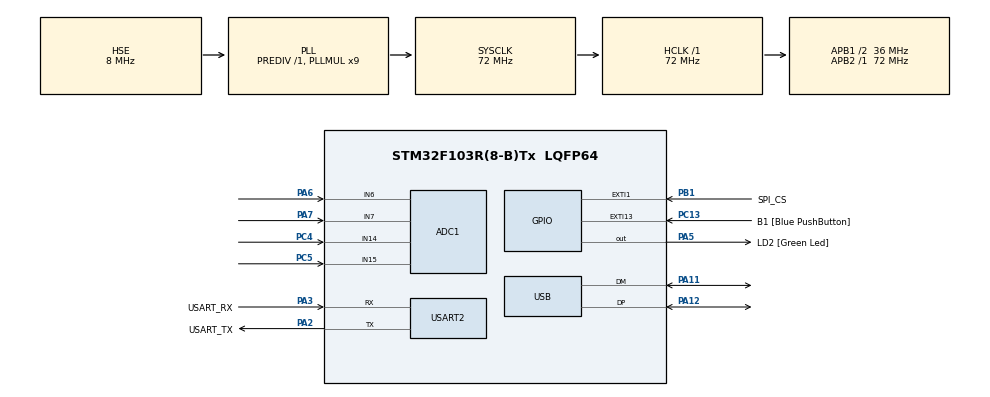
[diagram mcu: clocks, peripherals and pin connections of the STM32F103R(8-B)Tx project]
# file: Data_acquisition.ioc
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ADC1.Channel-6\#ChannelRegularConversion=ADC_CHANNEL_15
ADC1.Channel-7\#ChannelRegularConversion=ADC_CHANNEL_6
ADC1.Channel-9\#ChannelRegularConversion=ADC_CHANNEL_7
ADC1.ContinuousConvMode=ENABLE
ADC1.EnableRegularConversion=ENABLE
ADC1.ExternalTrigConv=ADC_SOFTWARE_START
ADC1.NbrOfConversion=3
ADC1.NbrOfConversionFlag=1
ADC1.Rank-6\#ChannelRegularConversion=1
ADC1.Rank-7\#ChannelRegularConversion=2
ADC1.Rank-9\#ChannelRegularConversion=3
ADC1.SamplingTime-6\#ChannelRegularConversion=ADC_SAMPLETIME_55CYCLES_5
ADC1.SamplingTime-7\#ChannelRegularConversion=ADC_SAMPLETIME_1CYCLE_5
ADC1.SamplingTime-9\#ChannelRegularConversion=ADC_SAMPLETIME_1CYCLE_5
ADC1.master=1
Dma.ADC1.0.Direction=DMA_PERIPH_TO_MEMORY
Dma.ADC1.0.Instance=DMA1_Channel1
Dma.ADC1.0.MemDataAlignment=DMA_MDATAALIGN_HALFWORD
Dma.ADC1.0.MemInc=DMA_MINC_ENABLE
Dma.ADC1.0.Mode=DMA_CIRCULAR
Dma.ADC1.0.PeriphDataAlignment=DMA_PDATAALIGN_HALFWORD
Dma.ADC1.0.PeriphInc=DMA_PINC_DISABLE
Dma.ADC1.0.Priority=DMA_PRIORITY_LOW
Dma.Request0=ADC1
Mcu.Family=STM32F1
Mcu.Name=STM32F103R(8-B)Tx
Mcu.Package=LQFP64
NVIC.DMA1_Channel1_IRQn=true\:0\:0\:false\:false\:true\:false\:true\:true
NVIC.EXTI15_10_IRQn=true\:0\:0\:false\:false\:true\:true\:true\:true
NVIC.EXTI1_IRQn=true\:0\:0\:false\:false\:true\:true\:true\:true
NVIC.PriorityGroup=NVIC_PRIORITYGROUP_4
NVIC.USB_LP_CAN1_RX0_IRQn=true\:0\:0\:false\:false\:true\:false\:true\:true
PA11.Mode=Device
PA11.Signal=USB_DM
PA12.Mode=Device
PA12.Signal=USB_DP
PA13.GPIO_Label=TMS
PA13.Mode=Serial_Wire
PA13.Signal=SYS_JTMS-SWDIO
PA14.GPIO_Label=TCK
PA14.Mode=Serial_Wire
PA14.Signal=SYS_JTCK-SWCLK
PA2.GPIO_Label=USART_TX
PA2.GPIO_Mode=GPIO_MODE_AF_PP
PA2.GPIO_PuPd=GPIO_NOPULL
PA2.GPIO_Speed=GPIO_SPEED_FREQ_LOW
PA2.Mode=Asynchronous
PA2.Signal=USART2_TX
PA3.GPIO_Label=USART_RX
PA3.GPIO_Mode=GPIO_MODE_AF_PP
PA3.GPIO_PuPd=GPIO_NOPULL
PA3.GPIO_Speed=GPIO_SPEED_FREQ_LOW
PA3.Mode=Asynchronous
PA3.Signal=USART2_RX
PA5.GPIO_Label=LD2 [Green Led]
PA5.GPIO_ModeDefaultOutputPP=GPIO_MODE_OUTPUT_PP
PA5.GPIO_PuPd=GPIO_NOPULL
PA5.GPIO_Speed=GPIO_SPEED_FREQ_LOW
PA5.Signal=GPIO_Output
PA6.Signal=ADCx_IN6
PA7.Signal=ADCx_IN7
PB1.GPIO_Label=SPI_CS
PB1.GPIO_ModeDefaultEXTI=GPIO_MODE_IT_FALLING
PB1.GPIO_PuPd=GPIO_NOPULL
PB1.Signal=GPXTI1
PB3.GPIO_Label=SWO
PB3.Signal=SYS_JTDO-TRACESWO
PC13-TAMPER-RTC.GPIO_Label=B1 [Blue PushButton]
PC13-TAMPER-RTC.GPIO_ModeDefaultEXTI=GPIO_MODE_IT_FALLING
PC13-TAMPER-RTC.GPIO_PuPd=GPIO_NOPULL
PC13-TAMPER-RTC.Signal=GPXTI13
PC14-OSC32_IN.Mode=LSE-External-Oscillator
PC14-OSC32_IN.Signal=RCC_OSC32_IN
PC15-OSC32_OUT.Mode=LSE-External-Oscillator
PC15-OSC32_OUT.Signal=RCC_OSC32_OUT
PC4.Signal=ADCx_IN14
PC5.Signal=ADCx_IN15
PD0-OSC_IN.Mode=HSE-External-Clock-Source
PD0-OSC_IN.Signal=RCC_OSC_IN
PD1-OSC_OUT.Mode=HSE-External-Clock-Source
PD1-OSC_OUT.Signal=RCC_OSC_OUT
ProjectManager.HeapSize=0x200
ProjectManager.StackSize=0x400
ProjectManager.TargetToolchain=STM32CubeIDE
RCC.ADCPresc=RCC_ADCPCLK2_DIV6
RCC.AHBFreq_Value=72000000
RCC.APB1CLKDivider=RCC_HCLK_DIV2
RCC.APB1Freq_Value=36000000
RCC.APB1TimFreq_Value=72000000
RCC.APB2Freq_Value=72000000
RCC.APB2TimFreq_Value=72000000
RCC.HCLKFreq_Value=72000000
RCC.PLLMUL=RCC_PLL_MUL9
RCC.PLLSourceVirtual=RCC_PLLSOURCE_HSE
RCC.RTCClockSelection=RCC_RTCCLKSOURCE_LSE
RCC.SYSCLKFreq_VALUE=72000000
RCC.SYSCLKSource=RCC_SYSCLKSOURCE_PLLCLK
RCC.USBFreq_Value=48000000
RCC.USBPrescaler=RCC_USBCLKSOURCE_PLL_DIV1_5
SH.ADCx_IN14.0=ADC1_IN14,IN14
SH.ADCx_IN15.0=ADC1_IN15,IN15
SH.ADCx_IN6.0=ADC1_IN6,IN6
SH.ADCx_IN7.0=ADC1_IN7,IN7
USART2.VirtualMode=VM_ASYNC
USB_DEVICE.CLASS_NAME_FS=CDC
USB_DEVICE.PRODUCT_STRING_CDC_FS=STM32 Virtual ComPort USB
USB_DEVICE.VirtualMode=Cdc
USB_DEVICE.VirtualModeFS=Cdc_FS
VP_USB_DEVICE_VS_USB_DEVICE_CDC_FS.Mode=CDC_FS
board=NUCLEO-F103RB

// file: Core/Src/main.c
/* USER CODE BEGIN Header */
/**
  ******************************************************************************
  * @file           : main.c
  * @brief          : Main program body
  ******************************************************************************
  * @attention
  *
  * Copyright (c) 2022 STMicroelectronics.
  * All rights reserved.
  *
  * This software is licensed under terms that can be found in the LICENSE file
  * in the root directory of this software component.
  * If no LICENSE file comes with this software, it is provided AS-IS.
  *
  ******************************************************************************
  */
/* USER CODE END Header */
#include "main.h"
#include "usb_device.h"

/* USER CODE BEGIN PD */
// Buffer length set at 6600 (2200 per one channel)
#define DMA_ADC_BUF (6600)
/* USER CODE END PD */

ADC_HandleTypeDef hadc1;
DMA_HandleTypeDef hdma_adc1;

UART_HandleTypeDef huart2;

/* USER CODE BEGIN PV */
volatile uint16_t adcResultsDMA[DMA_ADC_BUF];
/* USER CODE END PV */

void SystemClock_Config(void);
static void MX_GPIO_Init(void);
static void MX_DMA_Init(void);
static void MX_ADC1_Init(void);
static void MX_USART2_UART_Init(void);

int main(void)
{

  /* MCU Configuration--------------------------------------------------------*/

  /* Reset of all peripherals, Initializes the Flash interface and the Systick. */
  HAL_Init();

  /* Configure the system clock */
  SystemClock_Config();

  /* Initialize all configured peripherals */
  MX_GPIO_Init();
  MX_DMA_Init();
  MX_ADC1_Init();
  MX_USB_DEVICE_Init();
  MX_USART2_UART_Init();
  /* USER CODE BEGIN 2 */
  // Start of DMA ADC measurements
  HAL_ADC_Start_DMA(&hadc1, (uint32_t*)adcResultsDMA, DMA_ADC_BUF);
  /* USER CODE END 2 */

  /* Infinite loop */
  while (1)
  {

  }
}

void SystemClock_Config(void)
{
  RCC_OscInitTypeDef RCC_OscInitStruct = {0};
  RCC_ClkInitTypeDef RCC_ClkInitStruct = {0};
  RCC_PeriphCLKInitTypeDef PeriphClkInit = {0};

  /** Initializes the RCC Oscillators according to the specified parameters
  * in the RCC_OscInitTypeDef structure.
  */
  RCC_OscInitStruct.OscillatorType = RCC_OSCILLATORTYPE_HSE;
  RCC_OscInitStruct.HSEState = RCC_HSE_BYPASS;
  RCC_OscInitStruct.HSEPredivValue = RCC_HSE_PREDIV_DIV1;
  RCC_OscInitStruct.HSIState = RCC_HSI_ON;
  RCC_OscInitStruct.PLL.PLLState = RCC_PLL_ON;
  RCC_OscInitStruct.PLL.PLLSource = RCC_PLLSOURCE_HSE;
  RCC_OscInitStruct.PLL.PLLMUL = RCC_PLL_MUL9;
  if (HAL_RCC_OscConfig(&RCC_OscInitStruct) != HAL_OK)
  {
    Error_Handler();
  }

  /** Initializes the CPU, AHB and APB buses clocks
  */
  RCC_ClkInitStruct.ClockType = RCC_CLOCKTYPE_HCLK|RCC_CLOCKTYPE_SYSCLK
                              |RCC_CLOCKTYPE_PCLK1|RCC_CLOCKTYPE_PCLK2;
  RCC_ClkInitStruct.SYSCLKSource = RCC_SYSCLKSOURCE_PLLCLK;
  RCC_ClkInitStruct.AHBCLKDivider = RCC_SYSCLK_DIV1;
  RCC_ClkInitStruct.APB1CLKDivider = RCC_HCLK_DIV2;
  RCC_ClkInitStruct.APB2CLKDivider = RCC_HCLK_DIV1;

  if (HAL_RCC_ClockConfig(&RCC_ClkInitStruct, FLASH_LATENCY_2) != HAL_OK)
  {
    Error_Handler();
  }
  PeriphClkInit.PeriphClockSelection = RCC_PERIPHCLK_ADC|RCC_PERIPHCLK_USB;
  PeriphClkInit.AdcClockSelection = RCC_ADCPCLK2_DIV6;
  PeriphClkInit.UsbClockSelection = RCC_USBCLKSOURCE_PLL_DIV1_5;
  if (HAL_RCCEx_PeriphCLKConfig(&PeriphClkInit) != HAL_OK)
  {
    Error_Handler();
  }
}

static void MX_ADC1_Init(void)
{

  ADC_ChannelConfTypeDef sConfig = {0};

  /** Common config
  */
  hadc1.Instance = ADC1;
  hadc1.Init.ScanConvMode = ADC_SCAN_ENABLE;
  hadc1.Init.ContinuousConvMode = ENABLE;
  hadc1.Init.DiscontinuousConvMode = DISABLE;
  hadc1.Init.ExternalTrigConv = ADC_SOFTWARE_START;
  hadc1.Init.DataAlign = ADC_DATAALIGN_RIGHT;
  hadc1.Init.NbrOfConversion = 3;
  if (HAL_ADC_Init(&hadc1) != HAL_OK)
  {
    Error_Handler();
  }

  /** Configure Regular Channel
  */
  sConfig.Channel = ADC_CHANNEL_15;
  sConfig.Rank = ADC_REGULAR_RANK_1;
  sConfig.SamplingTime = ADC_SAMPLETIME_55CYCLES_5;
  if (HAL_ADC_ConfigChannel(&hadc1, &sConfig) != HAL_OK)
  {
    Error_Handler();
  }

  /** Configure Regular Channel
  */
  sConfig.Channel = ADC_CHANNEL_6;
  sConfig.Rank = ADC_REGULAR_RANK_2;
  sConfig.SamplingTime = ADC_SAMPLETIME_1CYCLE_5;
  if (HAL_ADC_ConfigChannel(&hadc1, &sConfig) != HAL_OK)
  {
    Error_Handler();
  }

  /** Configure Regular Channel
  */
  sConfig.Channel = ADC_CHANNEL_7;
  sConfig.Rank = ADC_REGULAR_RANK_3;
  if (HAL_ADC_ConfigChannel(&hadc1, &sConfig) != HAL_OK)
  {
    Error_Handler();
  }

}

static void MX_USART2_UART_Init(void)
{

  huart2.Instance = USART2;
  huart2.Init.BaudRate = 115200;
  huart2.Init.WordLength = UART_WORDLENGTH_8B;
  huart2.Init.StopBits = UART_STOPBITS_1;
  huart2.Init.Parity = UART_PARITY_NONE;
  huart2.Init.Mode = UART_MODE_TX_RX;
  huart2.Init.HwFlowCtl = UART_HWCONTROL_NONE;
  huart2.Init.OverSampling = UART_OVERSAMPLING_16;
  if (HAL_UART_Init(&huart2) != HAL_OK)
  {
    Error_Handler();
  }

}

static void MX_DMA_Init(void)
{

  /* DMA controller clock enable */
  __HAL_RCC_DMA1_CLK_ENABLE();

  /* DMA interrupt init */
  /* DMA1_Channel1_IRQn interrupt configuration */
  HAL_NVIC_SetPriority(DMA1_Channel1_IRQn, 0, 0);
  HAL_NVIC_EnableIRQ(DMA1_Channel1_IRQn);

}

static void MX_GPIO_Init(void)
{
  GPIO_InitTypeDef GPIO_InitStruct = {0};

  /* GPIO Ports Clock Enable */
  __HAL_RCC_GPIOC_CLK_ENABLE();
  __HAL_RCC_GPIOD_CLK_ENABLE();
  __HAL_RCC_GPIOA_CLK_ENABLE();
  __HAL_RCC_GPIOB_CLK_ENABLE();

  /*Configure GPIO pin Output Level */
  HAL_GPIO_WritePin(LD2_GPIO_Port, LD2_Pin, GPIO_PIN_RESET);

  /*Configure GPIO pin : B1_Pin */
  GPIO_InitStruct.Pin = B1_Pin;
  GPIO_InitStruct.Mode = GPIO_MODE_IT_FALLING;
  GPIO_InitStruct.Pull = GPIO_NOPULL;
  HAL_GPIO_Init(B1_GPIO_Port, &GPIO_InitStruct);

  /*Configure GPIO pin : LD2_Pin */
  GPIO_InitStruct.Pin = LD2_Pin;
  GPIO_InitStruct.Mode = GPIO_MODE_OUTPUT_PP;
  GPIO_InitStruct.Pull = GPIO_NOPULL;
  GPIO_InitStruct.Speed = GPIO_SPEED_FREQ_LOW;
  HAL_GPIO_Init(LD2_GPIO_Port, &GPIO_InitStruct);

  /*Configure GPIO pin : SPI_CS_Pin */
  GPIO_InitStruct.Pin = SPI_CS_Pin;
  GPIO_InitStruct.Mode = GPIO_MODE_IT_FALLING;
  GPIO_InitStruct.Pull = GPIO_NOPULL;
  HAL_GPIO_Init(SPI_CS_GPIO_Port, &GPIO_InitStruct);

  /* EXTI interrupt init*/
  HAL_NVIC_SetPriority(EXTI1_IRQn, 0, 0);
  HAL_NVIC_EnableIRQ(EXTI1_IRQn);

  HAL_NVIC_SetPriority(EXTI15_10_IRQn, 0, 0);
  HAL_NVIC_EnableIRQ(EXTI15_10_IRQn);

}

/* USER CODE BEGIN 4 */
// Measurements are done automatically using DMA and then send via USB
// when the buffer reaches half length and full length
void HAL_ADC_ConvHalfCpltCallback(ADC_HandleTypeDef *hadc)
{
	CDC_Transmit_FS(adcResultsDMA, sizeof(adcResultsDMA)/2);
}
void HAL_ADC_ConvCpltCallback(ADC_HandleTypeDef *hadc)
{
	CDC_Transmit_FS(adcResultsDMA + DMA_ADC_BUF/2, sizeof(adcResultsDMA)/2);
}
/* USER CODE END 4 */

void Error_Handler(void)
{
  __disable_irq();
  while (1)
  {
  }
}
